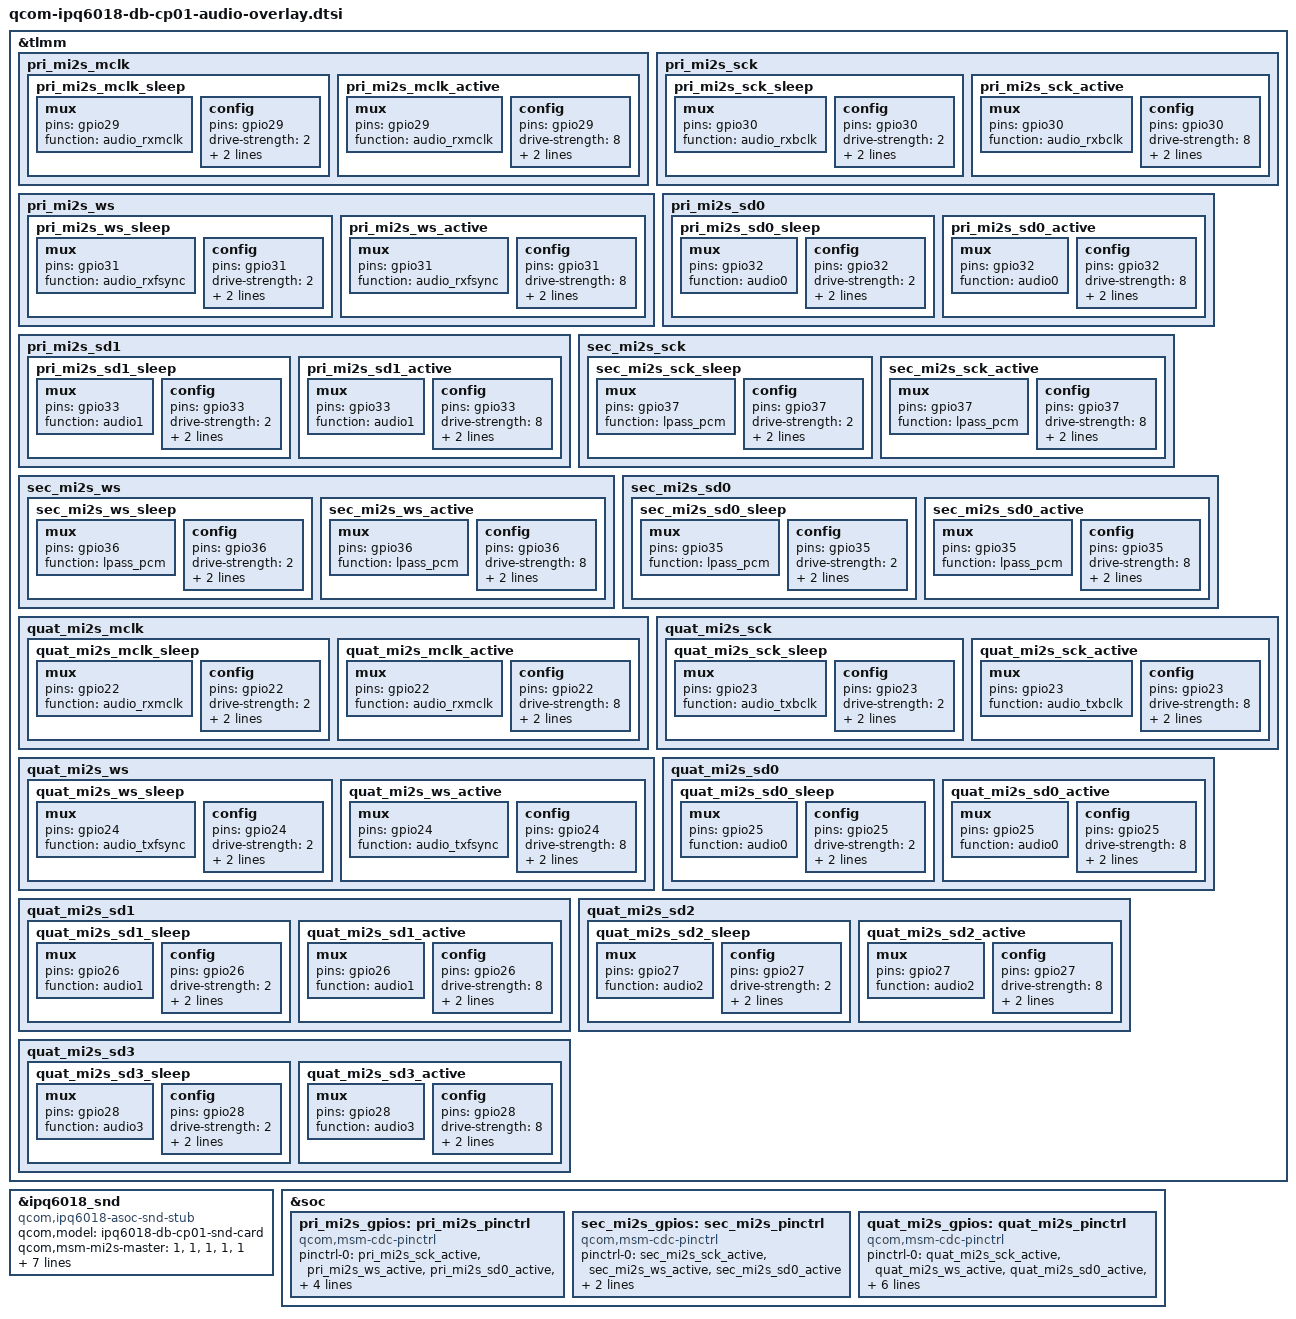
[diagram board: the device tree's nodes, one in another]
/*
 * Copyright (c) 2019, The Linux Foundation. All rights reserved.
 *
 * This program is free software; you can redistribute it and/or modify
 * it under the terms of the GNU General Public License version 2 and
 * only version 2 as published by the Free Software Foundation.
 *
 * This program is distributed in the hope that it will be useful,
 * but WITHOUT ANY WARRANTY; without even the implied warranty of
 * MERCHANTABILITY or FITNESS FOR A PARTICULAR PURPOSE.  See the
 * GNU General Public License for more details.
 */

#include <dt-bindings/clock/qcom,audio-ext-clk.h>
#include <dt-bindings/sound/audio-codec-port-types.h>
#include "qcom-ipq6018-audio.dtsi"

&tlmm {
	pri_mi2s_mclk {
		pri_mi2s_mclk_sleep: pri_mi2s_mclk_sleep {
			mux {
				pins = "gpio29";
				function = "audio_rxmclk";
			};

			config {
				pins = "gpio29";
				drive-strength = <2>;   /* 2 mA */
				bias-pull-down;         /* PULL DOWN */
				input-enable;
			};
		};

		pri_mi2s_mclk_active: pri_mi2s_mclk_active {
			mux {
				pins = "gpio29";
				function = "audio_rxmclk";
			};

			config {
				pins = "gpio29";
				drive-strength = <8>;   /* 8 mA */
				bias-disable;           /* NO PULL */
				output-high;
			};
		};
	};

	pri_mi2s_sck {
		pri_mi2s_sck_sleep: pri_mi2s_sck_sleep {
			mux {
				pins = "gpio30";
				function = "audio_rxbclk";
			};

			config {
				pins = "gpio30";
				drive-strength = <2>;   /* 2 mA */
				bias-pull-down;         /* PULL DOWN */
				input-enable;
			};
		};

		pri_mi2s_sck_active: pri_mi2s_sck_active {
			mux {
				pins = "gpio30";
				function = "audio_rxbclk";
			};

			config {
				pins = "gpio30";
				drive-strength = <8>;   /* 8 mA */
				bias-disable;           /* NO PULL */
				output-high;
			};
		};
	};

	pri_mi2s_ws {
		pri_mi2s_ws_sleep: pri_mi2s_ws_sleep {
			mux {
				pins = "gpio31";
				function = "audio_rxfsync";
			};

			config {
				pins = "gpio31";
				drive-strength = <2>;   /* 2 mA */
				bias-pull-down;         /* PULL DOWN */
				input-enable;
			};
		};

		pri_mi2s_ws_active: pri_mi2s_ws_active {
			mux {
				pins = "gpio31";
				function = "audio_rxfsync";
			};

			config {
				pins = "gpio31";
				drive-strength = <8>;   /* 8 mA */
				bias-disable;           /* NO PULL */
				output-high;
			};
		};
	};

	pri_mi2s_sd0 {
		pri_mi2s_sd0_sleep: pri_mi2s_sd0_sleep {
			mux {
				pins = "gpio32";
				function = "audio0";
			};

			config {
				pins = "gpio32";
				drive-strength = <2>;   /* 2 mA */
				bias-pull-down;         /* PULL DOWN */
				input-enable;
			};
		};

		pri_mi2s_sd0_active: pri_mi2s_sd0_active {
			mux {
				pins = "gpio32";
				function = "audio0";
			};

			config {
				pins = "gpio32";
				drive-strength = <8>;   /* 8 mA */
				bias-disable;           /* NO PULL */
				output-high;
			};
		};
	};

	pri_mi2s_sd1 {
		pri_mi2s_sd1_sleep: pri_mi2s_sd1_sleep {
			mux {
				pins = "gpio33";
				function = "audio1";
			};

			config {
				pins = "gpio33";
				drive-strength = <2>;   /* 2 mA */
				bias-pull-down;         /* PULL DOWN */
				input-enable;
			};
		};

		pri_mi2s_sd1_active: pri_mi2s_sd1_active {
			mux {
				pins = "gpio33";
				function = "audio1";
			};

			config {
				pins = "gpio33";
				drive-strength = <8>;   /* 8 mA */
				bias-disable;           /* NO PULL */
				output-high;
			};
		};
	};

	sec_mi2s_sck {
		sec_mi2s_sck_sleep: sec_mi2s_sck_sleep {
			mux {
				pins = "gpio37";
				function = "lpass_pcm";
			};

			config {
				pins = "gpio37";
				drive-strength = <2>;   /* 2 mA */
				bias-pull-down;         /* PULL DOWN */
				input-enable;
			};
		};

		sec_mi2s_sck_active: sec_mi2s_sck_active {
			mux {
				pins = "gpio37";
				function = "lpass_pcm";
			};

			config {
				pins = "gpio37";
				drive-strength = <8>;   /* 8 mA */
				bias-disable;           /* NO PULL */
				output-high;
			};
		};
	};

	sec_mi2s_ws {
		sec_mi2s_ws_sleep: sec_mi2s_ws_sleep {
			mux {
				pins = "gpio36";
				function = "lpass_pcm";
			};

			config {
				pins = "gpio36";
				drive-strength = <2>;   /* 2 mA */
				bias-pull-down;         /* PULL DOWN */
				input-enable;
			};
		};

		sec_mi2s_ws_active: sec_mi2s_ws_active {
			mux {
				pins = "gpio36";
				function = "lpass_pcm";
			};

			config {
				pins = "gpio36";
				drive-strength = <8>;   /* 8 mA */
				bias-disable;           /* NO PULL */
				output-high;
			};
		};
	};

	sec_mi2s_sd0 {
		sec_mi2s_sd0_sleep: sec_mi2s_sd0_sleep {
			mux {
				pins = "gpio35";
				function = "lpass_pcm";
			};

			config {
				pins = "gpio35";
				drive-strength = <2>;   /* 2 mA */
				bias-pull-down;         /* PULL DOWN */
				input-enable;
			};
		};

		sec_mi2s_sd0_active: sec_mi2s_sd0_active {
			mux {
				pins = "gpio35";
				function = "lpass_pcm";
			};

			config {
				pins = "gpio35";
				drive-strength = <8>;   /* 8 mA */
				bias-disable;           /* NO PULL */
				output-high;
			};
		};
	};

	quat_mi2s_mclk {
		quat_mi2s_mclk_sleep: quat_mi2s_mclk_sleep {
			mux {
				pins = "gpio22";
				function = "audio_rxmclk";
			};

			config {
				pins = "gpio22";
				drive-strength = <2>;   /* 2 mA */
				bias-pull-down;         /* PULL DOWN */
				input-enable;
			};
		};

		quat_mi2s_mclk_active: quat_mi2s_mclk_active {
			mux {
				pins = "gpio22";
				function = "audio_rxmclk";
			};

			config {
				pins = "gpio22";
				drive-strength = <8>;   /* 8 mA */
				bias-disable;           /* NO PULL */
				output-high;
			};
		};
	};

	quat_mi2s_sck {
		quat_mi2s_sck_sleep: quat_mi2s_sck_sleep {
			mux {
				pins = "gpio23";
				function = "audio_txbclk";
			};

			config {
				pins = "gpio23";
				drive-strength = <2>;   /* 2 mA */
				bias-pull-down;         /* PULL DOWN */
				input-enable;
			};
		};

		quat_mi2s_sck_active: quat_mi2s_sck_active {
			mux {
				pins = "gpio23";
				function = "audio_txbclk";
			};

			config {
				pins = "gpio23";
				drive-strength = <8>;   /* 8 mA */
				bias-disable;           /* NO PULL */
				output-high;
			};
		};
	};

	quat_mi2s_ws {
		quat_mi2s_ws_sleep: quat_mi2s_ws_sleep {
			mux {
				pins = "gpio24";
				function = "audio_txfsync";
			};

			config {
				pins = "gpio24";
				drive-strength = <2>;   /* 2 mA */
				bias-pull-down;         /* PULL DOWN */
				input-enable;
			};
		};

		quat_mi2s_ws_active: quat_mi2s_ws_active {
			mux {
				pins = "gpio24";
				function = "audio_txfsync";
			};

			config {
				pins = "gpio24";
				drive-strength = <8>;   /* 8 mA */
				bias-disable;           /* NO PULL */
				output-high;
			};
		};
	};

	quat_mi2s_sd0 {
		quat_mi2s_sd0_sleep: quat_mi2s_sd0_sleep {
			mux {
				pins = "gpio25";
				function = "audio0";
			};

			config {
				pins = "gpio25";
				drive-strength = <2>;   /* 2 mA */
				bias-pull-down;         /* PULL DOWN */
				input-enable;
			};
		};

		quat_mi2s_sd0_active: quat_mi2s_sd0_active {
			mux {
				pins = "gpio25";
				function = "audio0";
			};

			config {
				pins = "gpio25";
				drive-strength = <8>;   /* 8 mA */
				bias-disable;           /* NO PULL */
				output-high;
			};
		};
	};

	quat_mi2s_sd1 {
		quat_mi2s_sd1_sleep: quat_mi2s_sd1_sleep {
			mux {
				pins = "gpio26";
				function = "audio1";
			};

			config {
				pins = "gpio26";
				drive-strength = <2>;   /* 2 mA */
				bias-pull-down;         /* PULL DOWN */
				input-enable;
			};
		};

		quat_mi2s_sd1_active: quat_mi2s_sd1_active {
			mux {
				pins = "gpio26";
				function = "audio1";
			};

			config {
				pins = "gpio26";
				drive-strength = <8>;   /* 8 mA */
				bias-disable;           /* NO PULL */
				output-high;
			};
		};
	};

	quat_mi2s_sd2 {
		quat_mi2s_sd2_sleep: quat_mi2s_sd2_sleep {
			mux {
				pins = "gpio27";
				function = "audio2";
			};

			config {
				pins = "gpio27";
				drive-strength = <2>;   /* 2 mA */
				bias-pull-down;         /* PULL DOWN */
				input-enable;
			};
		};

		quat_mi2s_sd2_active: quat_mi2s_sd2_active {
			mux {
				pins = "gpio27";
				function = "audio2";
			};

			config {
				pins = "gpio27";
				drive-strength = <8>;   /* 8 mA */
				bias-disable;           /* NO PULL */
				output-high;
			};
		};
	};

	quat_mi2s_sd3 {
		quat_mi2s_sd3_sleep: quat_mi2s_sd3_sleep {
			mux {
				pins = "gpio28";
				function = "audio3";
			};

			config {
				pins = "gpio28";
				drive-strength = <2>;   /* 2 mA */
				bias-pull-down;         /* PULL DOWN */
				input-enable;
			};
		};

		quat_mi2s_sd3_active: quat_mi2s_sd3_active {
			mux {
				pins = "gpio28";
				function = "audio3";
			};

			config {
				pins = "gpio28";
				drive-strength = <8>;   /* 8 mA */
				bias-disable;           /* NO PULL */
				output-high;
			};
		};
	};
};

&ipq6018_snd {
	compatible = "qcom,ipq6018-asoc-snd-stub";
	qcom,model = "ipq6018-db-cp01-snd-card";
	qcom,msm-mi2s-master = <1>, <1>, <1>, <1>, <1>;
	qcom,audio-routing =
		"WSA_SPK2 OUT", "VA_MCLK";
	qcom,pri-mi2s-gpios = <&pri_mi2s_gpios>;
	qcom,sec-mi2s-gpios = <&sec_mi2s_gpios>;
	qcom,quat-mi2s-gpios = <&quat_mi2s_gpios>;
	asoc-codec  = <&stub_codec>;
	asoc-codec-names = "msm-stub-codec.1";
	qcom,msm_audio_ssr_devs = <&gecko_core_platform>;
};

&soc {
	pri_mi2s_gpios: pri_mi2s_pinctrl {
		compatible = "qcom,msm-cdc-pinctrl";
		pinctrl-names = "aud_active", "aud_sleep";
		pinctrl-0 = <&pri_mi2s_sck_active &pri_mi2s_ws_active
		&pri_mi2s_sd0_active &pri_mi2s_sd1_active>;
		pinctrl-1 = <&pri_mi2s_sck_sleep &pri_mi2s_ws_sleep
		&pri_mi2s_sd0_sleep &pri_mi2s_sd1_sleep>;
	};

	sec_mi2s_gpios: sec_mi2s_pinctrl {
		compatible = "qcom,msm-cdc-pinctrl";
		pinctrl-names = "aud_active", "aud_sleep";
		pinctrl-0 = <&sec_mi2s_sck_active &sec_mi2s_ws_active
		&sec_mi2s_sd0_active>;
		pinctrl-1 = <&sec_mi2s_sck_sleep &sec_mi2s_ws_sleep
		&sec_mi2s_sd0_sleep>;
	};

	quat_mi2s_gpios: quat_mi2s_pinctrl {
		compatible = "qcom,msm-cdc-pinctrl";
		pinctrl-names = "aud_active", "aud_sleep";
		pinctrl-0 = <&quat_mi2s_sck_active &quat_mi2s_ws_active
		&quat_mi2s_sd0_active &quat_mi2s_sd1_active
		&quat_mi2s_sd2_active &quat_mi2s_sd3_active>;
		pinctrl-1 = <&quat_mi2s_sck_sleep &quat_mi2s_ws_sleep
		&quat_mi2s_sd0_sleep &quat_mi2s_sd1_sleep
		&quat_mi2s_sd2_sleep &quat_mi2s_sd3_sleep>;
	};
};
